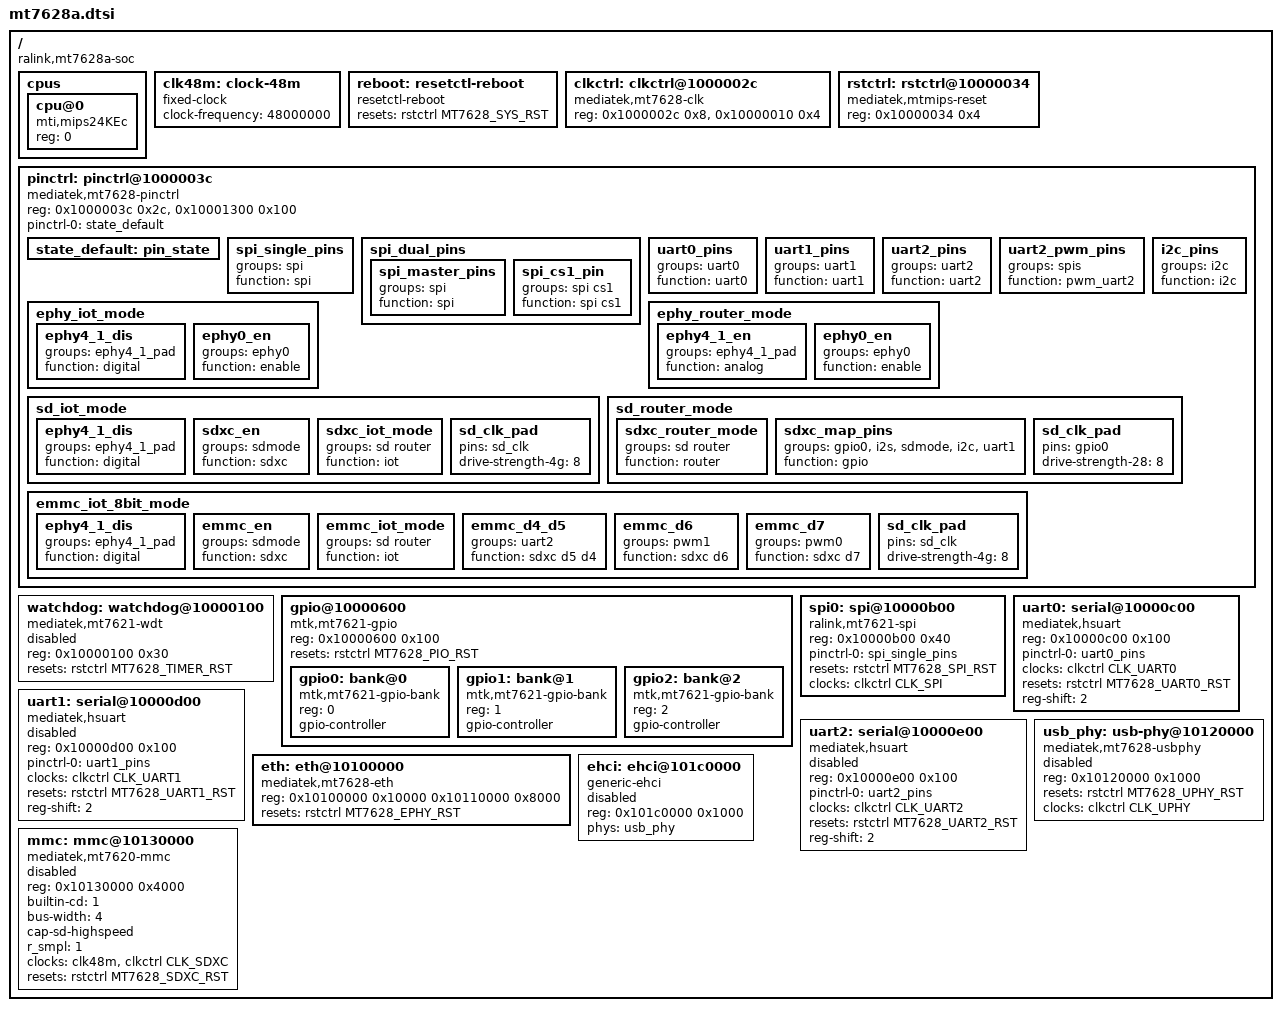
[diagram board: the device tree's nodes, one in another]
// SPDX-License-Identifier: GPL-2.0
#include <dt-bindings/clock/mt7628-clk.h>
#include <dt-bindings/reset/mt7628-reset.h>

/ {
	#address-cells = <1>;
	#size-cells = <1>;
	compatible = "ralink,mt7628a-soc";

	cpus {
		#address-cells = <1>;
		#size-cells = <0>;

		cpu@0 {
			compatible = "mti,mips24KEc";
			reg = <0>;
			device_type = "cpu";
		};
	};

	clk48m: clock-48m {
		compatible = "fixed-clock";

		clock-frequency = <48000000>;

		#clock-cells = <0>;
	};

	reboot: resetctl-reboot {
		compatible = "resetctl-reboot";

		resets = <&rstctrl MT7628_SYS_RST>;
		reset-names = "sysreset";
	};

	clkctrl: clkctrl@1000002c {
		compatible = "mediatek,mt7628-clk";
		reg = <0x1000002c 0x8>, <0x10000010 0x4>;
		reg-names = "syscfg0", "clkcfg";
		#clock-cells = <1>;
	};

	rstctrl: rstctrl@10000034 {
		compatible = "mediatek,mtmips-reset";
		reg = <0x10000034 0x4>;
		#reset-cells = <1>;
	};

	pinctrl: pinctrl@1000003c {
		compatible = "mediatek,mt7628-pinctrl";
		reg = <0x1000003c 0x2c>, <0x10001300 0x100>;
		reg-names = "gpiomode", "padconf";

		pinctrl-names = "default";
		pinctrl-0 = <&state_default>;

		state_default: pin_state {
		};

		spi_single_pins: spi_single_pins {
			groups = "spi";
			function = "spi";
		};

		spi_dual_pins: spi_dual_pins {
			spi_master_pins {
				groups = "spi";
				function = "spi";
			};

			spi_cs1_pin {
				groups = "spi cs1";
				function = "spi cs1";
			};
		};

		uart0_pins: uart0_pins {
			groups = "uart0";
			function = "uart0";
		};

		uart1_pins: uart1_pins {
			groups = "uart1";
			function = "uart1";
		};

		uart2_pins: uart2_pins {
			groups = "uart2";
			function = "uart2";
		};

		uart2_pwm_pins: uart2_pwm_pins {
			groups = "spis";
			function = "pwm_uart2";
		};

		i2c_pins: i2c_pins {
			groups = "i2c";
			function = "i2c";
		};

		ephy_iot_mode: ephy_iot_mode {
			ephy4_1_dis {
				groups = "ephy4_1_pad";
				function = "digital";
			};

			ephy0_en {
				groups = "ephy0";
				function = "enable";
			};
		};

		ephy_router_mode: ephy_router_mode {
			ephy4_1_en {
				groups = "ephy4_1_pad";
				function = "analog";
			};

			ephy0_en {
				groups = "ephy0";
				function = "enable";
			};
		};

		sd_iot_mode: sd_iot_mode {
			ephy4_1_dis {
				groups = "ephy4_1_pad";
				function = "digital";
			};

			sdxc_en {
				groups = "sdmode";
				function = "sdxc";
			};

			sdxc_iot_mode {
				groups = "sd router";
				function = "iot";
			};

			sd_clk_pad {
				pins = "sd_clk";
				drive-strength-4g = <8>;
			};
		};

		sd_router_mode: sd_router_mode {
			sdxc_router_mode {
				groups = "sd router";
				function = "router";
			};

			sdxc_map_pins {
				groups = "gpio0", "i2s", "sdmode", \
					 "i2c", "uart1";
				function = "gpio";
			};

			sd_clk_pad {
				pins = "gpio0";
				drive-strength-28 = <8>;
			};
		};

		emmc_iot_8bit_mode: emmc_iot_8bit_mode {
			ephy4_1_dis {
				groups = "ephy4_1_pad";
				function = "digital";
			};

			emmc_en {
				groups = "sdmode";
				function = "sdxc";
			};

			emmc_iot_mode {
				groups = "sd router";
				function = "iot";
			};

			emmc_d4_d5 {
				groups = "uart2";
				function = "sdxc d5 d4";
			};

			emmc_d6 {
				groups = "pwm1";
				function = "sdxc d6";
			};

			emmc_d7 {
				groups = "pwm0";
				function = "sdxc d7";
			};

			sd_clk_pad {
				pins = "sd_clk";
				drive-strength-4g = <8>;
			};
		};
	};

	watchdog: watchdog@10000100 {
		compatible = "mediatek,mt7621-wdt";
		reg = <0x10000100 0x30>;

		resets = <&rstctrl MT7628_TIMER_RST>;
		reset-names = "wdt";

		status = "disabled";
	};

	gpio@10000600 {
		compatible = "mtk,mt7621-gpio";
		reg = <0x10000600 0x100>;
		#address-cells = <1>;
		#size-cells = <0>;
		resets = <&rstctrl MT7628_PIO_RST>;
		reset-names = "pio";

		gpio0: bank@0 {
			compatible = "mtk,mt7621-gpio-bank";
			reg = <0>;
			gpio-controller;
			#gpio-cells = <2>;
		};

		gpio1: bank@1 {
			compatible = "mtk,mt7621-gpio-bank";
			reg = <1>;
			gpio-controller;
			#gpio-cells = <2>;
		};

		gpio2: bank@2 {
			compatible = "mtk,mt7621-gpio-bank";
			reg = <2>;
			gpio-controller;
			#gpio-cells = <2>;
		};
	};

	spi0: spi@10000b00 {
		compatible = "ralink,mt7621-spi";
		reg = <0x10000b00 0x40>;

		pinctrl-names = "default";
		pinctrl-0 = <&spi_single_pins>;

		resets = <&rstctrl MT7628_SPI_RST>;
		reset-names = "spi";

		#address-cells = <1>;
		#size-cells = <0>;

		clocks = <&clkctrl CLK_SPI>;
	};

	uart0: serial@10000c00 {
		compatible = "mediatek,hsuart", "ns16550a";
		reg = <0x10000c00 0x100>;

		pinctrl-names = "default";
		pinctrl-0 = <&uart0_pins>;

		clocks = <&clkctrl CLK_UART0>;

		resets = <&rstctrl MT7628_UART0_RST>;
		reset-names = "uart0";

		reg-shift = <2>;
	};

	uart1: serial@10000d00 {
		compatible = "mediatek,hsuart", "ns16550a";
		reg = <0x10000d00 0x100>;

		pinctrl-names = "default";
		pinctrl-0 = <&uart1_pins>;

		clocks = <&clkctrl CLK_UART1>;

		resets = <&rstctrl MT7628_UART1_RST>;
		reset-names = "uart1";

		reg-shift = <2>;

		status = "disabled";
	};

	uart2: serial@10000e00 {
		compatible = "mediatek,hsuart", "ns16550a";
		reg = <0x10000e00 0x100>;

		pinctrl-names = "default";
		pinctrl-0 = <&uart2_pins>;

		clocks = <&clkctrl CLK_UART2>;

		resets = <&rstctrl MT7628_UART2_RST>;
		reset-names = "uart2";

		reg-shift = <2>;

		status = "disabled";
	};

	eth: eth@10100000 {
		compatible = "mediatek,mt7628-eth";
		reg = <0x10100000 0x10000
		       0x10110000 0x8000>;

		resets = <&rstctrl MT7628_EPHY_RST>;
		reset-names = "ephy";
	};

	usb_phy: usb-phy@10120000 {
		compatible = "mediatek,mt7628-usbphy";
		reg = <0x10120000 0x1000>;

		#phy-cells = <0>;

		resets = <&rstctrl MT7628_UPHY_RST>;
		reset-names = "phy";

		clocks = <&clkctrl CLK_UPHY>;
		clock-names = "cg";

		status = "disabled";
	};

	ehci: ehci@101c0000 {
		compatible = "generic-ehci";
		reg = <0x101c0000 0x1000>;

		phys = <&usb_phy>;
		phy-names = "usb";

		status = "disabled";
	};

	mmc: mmc@10130000 {
		compatible = "mediatek,mt7620-mmc";
		reg = <0x10130000 0x4000>;
		builtin-cd = <1>;
		bus-width = <4>;
		cap-sd-highspeed;
		r_smpl = <1>;

		clocks = <&clk48m>, <&clkctrl CLK_SDXC>;
		clock-names = "source", "hclk";

		resets = <&rstctrl MT7628_SDXC_RST>;

		status = "disabled";
	};
};
